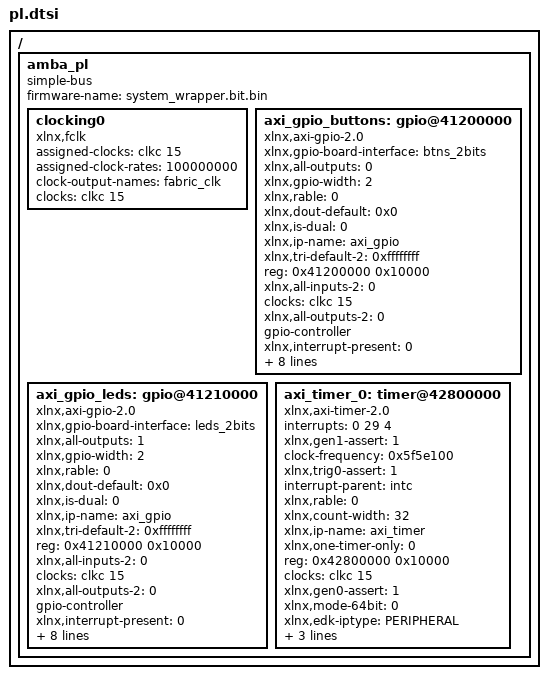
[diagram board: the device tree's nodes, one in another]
/ {
	amba_pl: amba_pl {
		ranges;
		compatible = "simple-bus";
		#address-cells = <1>;
		#size-cells = <1>;
		firmware-name = "system_wrapper.bit.bin";
		clocking0: clocking0 {
			compatible = "xlnx,fclk";
			assigned-clocks = <&clkc 15>;
			assigned-clock-rates = <100000000>;
			#clock-cells = <0>;
			clock-output-names = "fabric_clk";
			clocks = <&clkc 15>;
		};
		axi_gpio_buttons: gpio@41200000 {
			xlnx,gpio-board-interface = "btns_2bits";
			compatible = "xlnx,axi-gpio-2.0" , "xlnx,xps-gpio-1.00.a";
			xlnx,all-outputs = <0>;
			#gpio-cells = <2>;
			xlnx,gpio-width = <2>;
			xlnx,rable = <0>;
			xlnx,dout-default = <0x0>;
			xlnx,is-dual = <0>;
			xlnx,ip-name = "axi_gpio";
			xlnx,tri-default-2 = <0xffffffff>;
			reg = <0x41200000 0x10000>;
			xlnx,all-inputs-2 = <0>;
			clocks = <&clkc 15>;
			xlnx,all-outputs-2 = <0>;
			gpio-controller;
			xlnx,interrupt-present = <0>;
			xlnx,gpio2-board-interface = "Custom";
			xlnx,edk-iptype = "PERIPHERAL";
			xlnx,dout-default-2 = <0x0>;
			status = "okay";
			xlnx,gpio2-width = <32>;
			clock-names = "s_axi_aclk";
			xlnx,use-board-flow;
			xlnx,tri-default = <0xffffffff>;
			xlnx,name = "axi_gpio_buttons";
			xlnx,all-inputs = <1>;
		};
		axi_gpio_leds: gpio@41210000 {
			xlnx,gpio-board-interface = "leds_2bits";
			compatible = "xlnx,axi-gpio-2.0" , "xlnx,xps-gpio-1.00.a";
			xlnx,all-outputs = <1>;
			#gpio-cells = <2>;
			xlnx,gpio-width = <2>;
			xlnx,rable = <0>;
			xlnx,dout-default = <0x0>;
			xlnx,is-dual = <0>;
			xlnx,ip-name = "axi_gpio";
			xlnx,tri-default-2 = <0xffffffff>;
			reg = <0x41210000 0x10000>;
			xlnx,all-inputs-2 = <0>;
			clocks = <&clkc 15>;
			xlnx,all-outputs-2 = <0>;
			gpio-controller;
			xlnx,interrupt-present = <0>;
			xlnx,gpio2-board-interface = "Custom";
			xlnx,edk-iptype = "PERIPHERAL";
			xlnx,dout-default-2 = <0x0>;
			status = "okay";
			xlnx,gpio2-width = <32>;
			clock-names = "s_axi_aclk";
			xlnx,use-board-flow;
			xlnx,tri-default = <0xffffffff>;
			xlnx,name = "axi_gpio_leds";
			xlnx,all-inputs = <0>;
		};
		axi_timer_0: timer@42800000 {
			interrupts = < 0 29 4 >;
			compatible = "xlnx,axi-timer-2.0" , "xlnx,xps-timer-1.00.a";
			xlnx,gen1-assert = <1>;
			clock-frequency = <0x5f5e100>;
			xlnx,trig0-assert = <1>;
			interrupt-parent = <&intc>;
			xlnx,rable = <0>;
			xlnx,count-width = <32>;
			xlnx,ip-name = "axi_timer";
			xlnx,one-timer-only = <0>;
			reg = <0x42800000 0x10000>;
			clocks = <&clkc 15>;
			xlnx,gen0-assert = <1>;
			xlnx,mode-64bit = <0>;
			xlnx,edk-iptype = "PERIPHERAL";
			status = "okay";
			xlnx,trig1-assert = <1>;
			clock-names = "s_axi_aclk";
			xlnx,enable-timer2 = <1>;
			interrupt-names = "interrupt";
			xlnx,name = "axi_timer_0";
		};
	};
};
